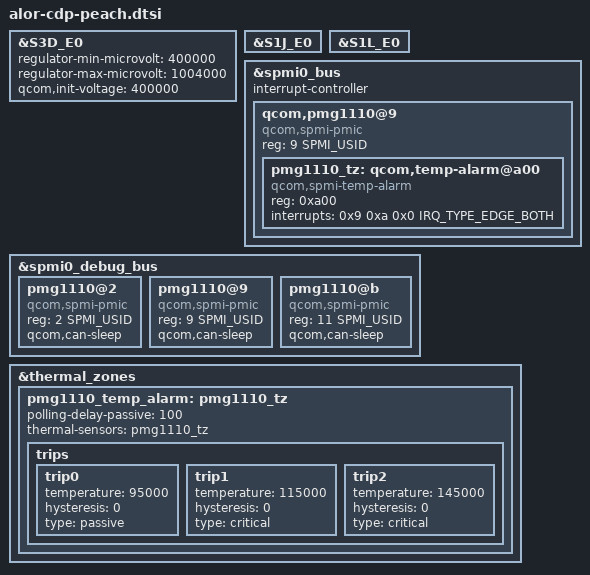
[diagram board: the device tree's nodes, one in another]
// SPDX-License-Identifier: BSD-3-Clause
/*
 * Copyright (c) Qualcomm Technologies, Inc. and/or its subsidiaries.
 */

#include "alor-cdp.dtsi"

&S3D_E0 {
	regulator-min-microvolt = <400000>;
	regulator-max-microvolt = <1004000>;
	qcom,init-voltage = <400000>;
};

&S1J_E0 {
	status = "ok";
};

&S1L_E0 {
	status = "ok";
};

&spmi0_bus {
	#address-cells = <2>;
	#size-cells = <0>;
	interrupt-controller;
	#interrupt-cells = <4>;

	qcom,pmg1110@9 {
		compatible = "qcom,spmi-pmic";
		reg = <9 SPMI_USID>;
		#address-cells = <1>;
		#size-cells = <0>;

		pmg1110_tz: qcom,temp-alarm@a00 {
			compatible = "qcom,spmi-temp-alarm";
			reg = <0xa00>;
			interrupts = <0x9 0xa 0x0 IRQ_TYPE_EDGE_BOTH>;
			#thermal-sensor-cells = <0>;
		};
	};
};

&spmi0_debug_bus {
	pmg1110@2 {
		compatible = "qcom,spmi-pmic";
		reg = <2 SPMI_USID>;
		#address-cells = <2>;
		#size-cells = <0>;
		qcom,can-sleep;
	};

	pmg1110@9 {
		compatible = "qcom,spmi-pmic";
		reg = <9 SPMI_USID>;
		#address-cells = <2>;
		#size-cells = <0>;
		qcom,can-sleep;
	};

	pmg1110@b {
		compatible = "qcom,spmi-pmic";
		reg = <11 SPMI_USID>;
		#address-cells = <2>;
		#size-cells = <0>;
		qcom,can-sleep;
	};
};

&thermal_zones {
	pmg1110_temp_alarm: pmg1110_tz {
		polling-delay-passive = <100>;
		thermal-sensors = <&pmg1110_tz>;

		trips {
			trip0 {
				temperature = <95000>;
				hysteresis = <0>;
				type = "passive";
			};

			trip1 {
				temperature = <115000>;
				hysteresis = <0>;
				type = "critical";
			};

			trip2 {
				temperature = <145000>;
				hysteresis = <0>;
				type = "critical";
			};
		};
	};
};
